# CLOCKALIAS32 register map
File version: 1.0
E07 tested: exact <PERIPH>EN, underscore alias <PERIPH>_EN, and a decoy prefix
Registers are access not given, no defined reset value unless marked. A register's access mark holds for its fields unless they carry their own. Offsets are from the block's base; lines under a group give offsets from that group; [hi:lo] are bit positions; {n}, {i} and the like mark numbered series; 'fields as' and 'values as' point back to an identical list; <NAME> marks a mode.

## Memory map
0x40004400 USART2
0x40013800 USART1
0x40021000 RCC

## RCC
Base 0x40021000
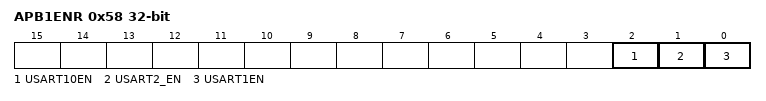
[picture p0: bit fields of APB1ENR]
0x58 APB1ENR
  [2] USART10EN, [1] USART2_EN, [0] USART1EN

## USART1
Base 0x40013800
Same registers: USART2 0x40004400
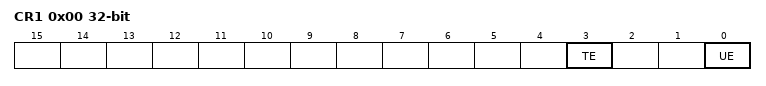
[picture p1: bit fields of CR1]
0x00 CR1
  [3] TE, [0] UE
